# BS2X register map
File version: 0.1
CPU: other r0p0, little endian, MPU, FPU, 3 interrupt priority bits
Registers are 32-bit, read-write, reset 0x0 unless marked. A register's access mark holds for its fields unless they carry their own. Offsets are from the block's base; [hi:lo] are bit positions; {n}, {i} and the like mark numbered series.

## GLB_CTL_M — Main core global control - BCPU/MCPU reset status, chip reset, AON CRG
Base 0x57000000
0x30 BCPU_RESET_STS — BCPU reset status register
  [31:0] bcpu_reset_sts ro — BCPU reset status
0x34 MCPU_RESET_STS — MCPU reset status register
  [31:0] mcpu_reset_sts ro — MCPU reset status
0x3C RESET_STS_CLEAR wo — Reset status clear register
  [31:0] rst_sts_clear — Write 0xFF to clear all reset status bits
0x100 AON_CRG_CKEN_CTL — AON CRG clock enable control
  [4] wdt_gate — WDT clock gate control at bit[4]
0x110 CHIP_RESET — Chip reset control register
  [2] chip_reset_en — Chip reset enable: 1=assert chip reset
0x110 AON_SOFT_RST_CTL — AON soft reset control
  [1] wdt_soft_rst — WDT soft reset at bit[1]

## GPIO0 — GPIO controller for GPIO[7:0]
Base 0x57010000
Same registers: GPIO1 0x57014000, GPIO2 0x57018000, GPIO3 0x5701C000, GPIO4 0x57020000, ULP_GPIO 0x57030000
0x00 GPIO_SW_OUT — GPIO data register
  [7:0] gpio_sw_out — GPIO data. Output: written value drives I/O; Input: reads external port
0x04 GPIO_SW_OEN reset 0xFF — GPIO data direction register
  [7:0] gpio_sw_oen — GPIO direction: 0=output; 1=input (default)
    0=Output direction; 1=Input direction
0x0C GPIO_INT_EN — GPIO interrupt enable register
  [7:0] gpio_int_en — Interrupt enable: 0=normal GPIO; 1=interrupt port
0x10 GPIO_INT_MASK — GPIO interrupt mask register
  [7:0] gpio_int_mask — Interrupt mask: 0=not masked; 1=masked
0x14 GPIO_INT_TYPE — GPIO interrupt type register
  [7:0] gpio_int_type — Interrupt type: 0=level; 1=edge
    0=Level-sensitive; 1=Edge-triggered
0x18 GPIO_INT_POLARITY — GPIO interrupt polarity register
  [7:0] gpio_int_polarity — Interrupt polarity: 0=low/falling; 1=high/rising
    0=LowFalling (Low level or falling edge); 1=HighRising (High level or rising edge)
0x1C GPIO_INT_DEDGE — GPIO dual-edge interrupt enable register
  [7:0] gpio_int_dedge — Dual-edge interrupt enable: 0=disabled; 1=enabled
    0=Disabled (Single-edge mode); 1=Enabled (Dual-edge triggered)
0x20 GPIO_INT_DEBOUNCE — GPIO interrupt debounce control register
  [7:0] gpio_int_debounce — Debounce enable: 0=disabled; 1=enabled
0x24 GPIO_INT_RAW — GPIO raw interrupt status register
  [7:0] gpio_int_raw ro — Raw interrupt status (before mask): 0=no interrupt; 1=interrupt
0x28 GPIO_INTR — GPIO interrupt status register
  [7:0] gpio_intr ro — Interrupt status (after mask): 0=no interrupt; 1=interrupt
0x2C GPIO_INT_EOI — GPIO interrupt clear register
  [7:0] gpio_int_eoi wo — Edge interrupt clear: 0=no clear; 1=clear interrupt
0x30 GPIO_DATA_SET
  [7:0] gpio_data_set wo — Write 1 to set corresponding GPIO_SW_OUT bits
0x34 GPIO_DATA_CLR — GPIO data clear register
  [7:0] gpio_data_clr wo — Write 1 to clear corresponding GPIO_SW_OUT bits

## TIMER — Timer module with 3 independent 32-bit timers (v150)
Base 0x52002000
0x60 ABNOR_INTR_RAW — Abnormal interrupt raw status
  [2:0] abnor_intr_raw ro — Abnormal interrupt raw status for all timers
0x64 ABNOR_IMSK — Abnormal interrupt mask
  [2:0] abnor_imsk — Abnormal interrupt mask for all timers
0x68 ABNOR_INTR_STAT — Abnormal interrupt status
  [2:0] abnor_intr_stat ro — Abnormal interrupt status for all timers
0x78 EOI_REN — End-of-interrupt register
  [2:0] eoi ro — Clear interrupts for all timers (read to clear)
0x7C RAW_INTR_STAT — Raw interrupt status
  [2:0] raw_intr ro — Raw interrupt status for all timers
0x80 INTR_STAT — Interrupt status (masked)
  [2:0] intr_stat ro — Interrupt status for all timers (after mask)
{0x100+0x100*i} TIMER{i}_LOAD_COUNT (i=0..2) — Timer {i} [dim=3] load count
  [31:0] load_count — Timer 0 load count value
{0x108+0x100*i} TIMER{i}_CURRENT_VALUE (i=0..2) — Timer {i} [dim=3] current value
  [31:0] current_value ro — Timer 0 current count value
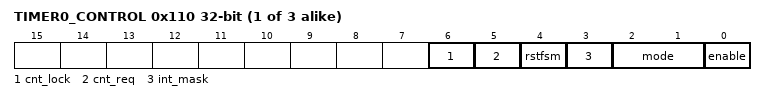
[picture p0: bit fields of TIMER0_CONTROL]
{0x110+0x100*i} TIMER{i}_CONTROL (i=0..2) — Timer {i} [dim=3] control register
  [6] cnt_lock ro — Current-count latch valid (TIMER_V150): set by HW after a cnt_req snapshot completes; poll until 1 before reading the current-value register.
  [5] cnt_req — Current-count latch request (TIMER_V150): write 1 to snapshot the live down-counter into the current-value register; the HW asserts cnt_lock when the snapshot is ready. Required to read a fresh count on silicon (the current-value register is a latch, not a live counter).
  [4] rstfsm wo — Reset FSM: 1=reset timer FSM
  [3] int_mask — Interrupt mask: 0=unmasked; 1=masked
  [2:1] mode — Timer mode (TIMER_V150, per vendor control_reg_mode_v150_t): 0=one-shot; 1=periodic; 3=free-run (2 is a one-shot alias)
    0=One-shot mode; 1=Periodic mode; 3=Free-running mode
  [0] enable — Timer enable: 0=disabled; 1=enabled
{0x114+0x100*i} TIMER{i}_EOI (i=0..2) — Timer {i} [dim=3] end-of-interrupt
  [0] eoi ro — Read to clear timer 0 interrupt
{0x118+0x100*i} TIMER{i}_RAW_INTR (i=0..2) — Timer {i} [dim=3] raw interrupt status
  [0] raw_intr ro — Raw interrupt status
